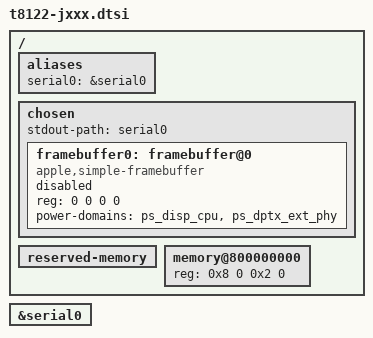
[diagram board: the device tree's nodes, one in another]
// SPDX-License-Identifier: GPL-2.0+ OR MIT
/*
 * Apple M3 MacBook Air/Pro and iMac (M3, 2023/2024)
 *
 * This file contains parts common to all Apple M3 devices using the t8122.
 *
 * target-type: J433, J434, J504, J613, J615
 *
 * Copyright The Asahi Linux Contributors
 */

/ {
	aliases {
		serial0 = &serial0;
	};

	chosen {
		#address-cells = <2>;
		#size-cells = <2>;
		ranges;

		stdout-path = "serial0";

		framebuffer0: framebuffer@0 {
			compatible = "apple,simple-framebuffer", "simple-framebuffer";
			reg = <0 0 0 0>; /* To be filled by loader */
			power-domains = <&ps_disp_cpu>, <&ps_dptx_ext_phy>;
			/* Format properties will be added by loader */
			status = "disabled";
		};
	};

	reserved-memory {
		#address-cells = <2>;
		#size-cells = <2>;
		ranges;
		/* To be filled by loader */
	};

	memory@800000000 {
		device_type = "memory";
		reg = <0x8 0 0x2 0>; /* To be filled by loader */
	};
};

&serial0 {
	status = "okay";
};
